VERSION ""

NS_ :

BS_:

BU_: mRFRM
VAL_TABLE_ VT_Fuse_status 3 "Not installed" 2 "Fault" 1 "Fuse powered" 0 "Fuse not powered" ;
VAL_TABLE_ VT_Relay_status 3 "Not installed" 2 "Reserved" 1 "Relay on" 0 "Relay off" ;
VAL_TABLE_ VT_Default_states 1 "Default state on" 0 "Default state off" ;
VAL_TABLE_ VT_Relay_state 3 "Do not change relay state" 2 "Reserved" 1 "Turn relay on" 0 "Turn relay off" ;

BO_ 2566698400 View_Fuse_Status: 8 mRFRM
 SG_ Fuse9_status : 22|2@1+ (1,0) [0|3] "" Vector__XXX
 SG_ Fuse8_status : 8|2@1+ (1,0) [0|3] "" Vector__XXX
 SG_ Fuse7_status : 10|2@1+ (1,0) [0|3] "" Vector__XXX
 SG_ Fuse6_status : 12|2@1+ (1,0) [0|3] "" Vector__XXX
 SG_ Fuse5_status : 14|2@1+ (1,0) [0|3] "" Vector__XXX
 SG_ Fuse4_status : 0|2@1+ (1,0) [0|3] "" Vector__XXX
 SG_ Fuse3_status : 2|2@1+ (1,0) [0|3] "" Vector__XXX
 SG_ Fuse2_status : 4|2@1+ (1,0) [0|3] "" Vector__XXX
 SG_ Fuse28_status : 48|2@1+ (1,0) [0|3] "" Vector__XXX
 SG_ Fuse27_status : 50|2@1+ (1,0) [0|3] "" Vector__XXX
 SG_ Fuse26_status : 52|2@1+ (1,0) [0|3] "" Vector__XXX
 SG_ Fuse25_status : 54|2@1+ (1,0) [0|3] "" Vector__XXX
 SG_ Fuse24_status : 40|2@1+ (1,0) [0|3] "" Vector__XXX
 SG_ Fuse23_status : 42|2@1+ (1,0) [0|3] "" Vector__XXX
 SG_ Fuse22_status : 44|2@1+ (1,0) [0|3] "" Vector__XXX
 SG_ Fuse21_status : 46|2@1+ (1,0) [0|3] "" Vector__XXX
 SG_ Fuse20_status : 32|2@1+ (1,0) [0|3] "" Vector__XXX
 SG_ Fuse1_status : 6|2@1+ (1,0) [0|3] "" Vector__XXX
 SG_ Fuse19_status : 34|2@1+ (1,0) [0|3] "" Vector__XXX
 SG_ Fuse18_status : 36|2@1+ (1,0) [0|3] "" Vector__XXX
 SG_ Fuse17_status : 38|2@1+ (1,0) [0|3] "" Vector__XXX
 SG_ Fuse16_status : 24|2@1+ (1,0) [0|3] "" Vector__XXX
 SG_ Fuse15_status : 26|2@1+ (1,0) [0|3] "" Vector__XXX
 SG_ Fuse14_status : 28|2@1+ (1,0) [0|3] "" Vector__XXX
 SG_ Fuse13_status : 30|2@1+ (1,0) [0|3] "" Vector__XXX
 SG_ Fuse12_status : 16|2@1+ (1,0) [0|3] "" Vector__XXX
 SG_ Fuse11_status : 18|2@1+ (1,0) [0|3] "" Vector__XXX
 SG_ Fuse10_status : 20|2@1+ (1,0) [0|3] "" Vector__XXX

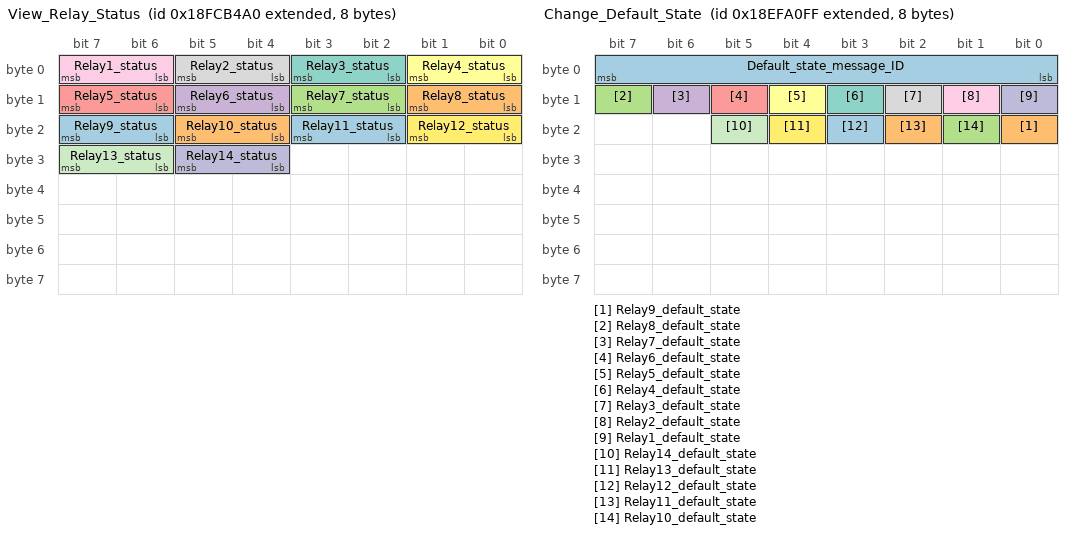
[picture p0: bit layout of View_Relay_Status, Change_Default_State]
BO_ 2566698144 View_Relay_Status: 8 mRFRM
 SG_ Relay9_status : 22|2@1+ (1,0) [0|3] "" Vector__XXX
 SG_ Relay8_status : 8|2@1+ (1,0) [0|3] "" Vector__XXX
 SG_ Relay7_status : 10|2@1+ (1,0) [0|3] "" Vector__XXX
 SG_ Relay6_status : 12|2@1+ (1,0) [0|3] "" Vector__XXX
 SG_ Relay5_status : 14|2@1+ (1,0) [0|3] "" Vector__XXX
 SG_ Relay4_status : 0|2@1+ (1,0) [0|3] "" Vector__XXX
 SG_ Relay3_status : 2|2@1+ (1,0) [0|3] "" Vector__XXX
 SG_ Relay2_status : 4|2@1+ (1,0) [0|3] "" Vector__XXX
 SG_ Relay1_status : 6|2@1+ (1,0) [0|3] "" Vector__XXX
 SG_ Relay14_status : 28|2@1+ (1,0) [0|3] "" Vector__XXX
 SG_ Relay13_status : 30|2@1+ (1,0) [0|3] "" Vector__XXX
 SG_ Relay12_status : 16|2@1+ (1,0) [0|3] "" Vector__XXX
 SG_ Relay11_status : 18|2@1+ (1,0) [0|3] "" Vector__XXX
 SG_ Relay10_status : 20|2@1+ (1,0) [0|3] "" Vector__XXX

BO_ 2565841151 Change_Default_State: 8 mRFRM
 SG_ Default_state_message_ID : 0|8@1+ (1,0) [0|255] "" Vector__XXX
 SG_ Relay9_default_state : 16|1@1+ (1,0) [0|1] "" Vector__XXX
 SG_ Relay8_default_state : 15|1@1+ (1,0) [0|1] "" Vector__XXX
 SG_ Relay7_default_state : 14|1@1+ (1,0) [0|1] "" Vector__XXX
 SG_ Relay6_default_state : 13|1@1+ (1,0) [0|1] "" Vector__XXX
 SG_ Relay5_default_state : 12|1@1+ (1,0) [0|1] "" Vector__XXX
 SG_ Relay4_default_state : 11|1@1+ (1,0) [0|1] "" Vector__XXX
 SG_ Relay3_default_state : 10|1@1+ (1,0) [0|1] "" Vector__XXX
 SG_ Relay2_default_state : 9|1@1+ (1,0) [0|1] "" Vector__XXX
 SG_ Relay1_default_state : 8|1@1+ (1,0) [0|1] "" Vector__XXX
 SG_ Relay14_default_state : 21|1@1+ (1,0) [0|1] "" Vector__XXX
 SG_ Relay13_default_state : 20|1@1+ (1,0) [0|1] "" Vector__XXX
 SG_ Relay12_default_state : 19|1@1+ (1,0) [0|1] "" Vector__XXX
 SG_ Relay11_default_state : 18|1@1+ (1,0) [0|1] "" Vector__XXX
 SG_ Relay10_default_state : 17|1@1+ (1,0) [0|1] "" Vector__XXX

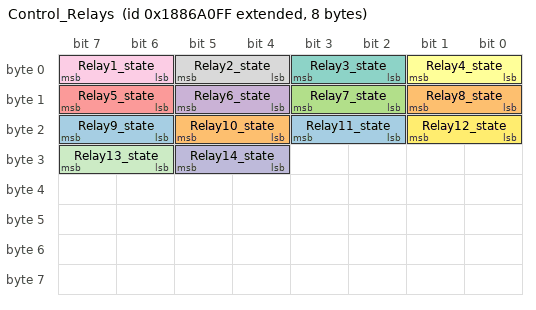
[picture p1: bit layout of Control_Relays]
BO_ 2558959871 Control_Relays: 8 mRFRM
 SG_ Relay9_state : 22|2@1+ (1,0) [0|3] "" Vector__XXX
 SG_ Relay8_state : 8|2@1+ (1,0) [0|3] "" Vector__XXX
 SG_ Relay7_state : 10|2@1+ (1,0) [0|3] "" Vector__XXX
 SG_ Relay6_state : 12|2@1+ (1,0) [0|3] "" Vector__XXX
 SG_ Relay5_state : 14|2@1+ (1,0) [0|3] "" Vector__XXX
 SG_ Relay4_state : 0|2@1+ (1,0) [0|3] "" Vector__XXX
 SG_ Relay3_state : 2|2@1+ (1,0) [0|3] "" Vector__XXX
 SG_ Relay2_state : 4|2@1+ (1,0) [0|3] "" Vector__XXX
 SG_ Relay1_state : 6|2@1+ (1,0) [0|3] "" Vector__XXX
 SG_ Relay14_state : 28|2@1+ (1,0) [0|3] "" Vector__XXX
 SG_ Relay13_state : 30|2@1+ (1,0) [0|3] "" Vector__XXX
 SG_ Relay12_state : 16|2@1+ (1,0) [0|3] "" Vector__XXX
 SG_ Relay11_state : 18|2@1+ (1,0) [0|3] "" Vector__XXX
 SG_ Relay10_state : 20|2@1+ (1,0) [0|3] "" Vector__XXX

CM_ BO_ 2565841151 "Set message ID to 0x79 to change default state";
BA_DEF_ SG_  "SigType" ENUM  "Default","Range","RangeSigned","ASCII","Discrete","Control","ReferencePGN","DTC","StringDelimiter","StringLength","StringLengthControl","MessageCounter","MessageChecksum";
BA_DEF_ SG_  "GenSigEVName" STRING ;
BA_DEF_ SG_  "GenSigILSupport" ENUM  "No","Yes";
BA_DEF_ SG_  "GenSigSendType" ENUM  "Cyclic","OnWrite","OnWriteWithRepetition","OnChange","OnChangeWithRepetition","IfActive","IfActiveWithRepetition","NoSigSendType";
BA_DEF_ BO_  "GenMsgCycleTimeFast" INT 0 3600000;
BA_DEF_ BO_  "GenMsgILSupport" ENUM  "No","Yes";
BA_DEF_ BO_  "GenMsgStartDelayTime" INT 0 100000;
BA_DEF_ BU_  "NmStationAddress" INT 0 255;
BA_DEF_ BO_  "GenMsgSendType" ENUM  "cyclic","NotUsed","IfActive","NotUsed","NotUsed","NotUsed","NotUsed","NotUsed","noMsgSendType";
BA_DEF_ BO_  "GenMsgRequestable" INT 0 1;
BA_DEF_ BO_  "GenMsgCycleTime" INT 0 3600000;
BA_DEF_  "DBName" STRING ;
BA_DEF_  "BusType" STRING ;
BA_DEF_DEF_  "SigType" "Default";
BA_DEF_DEF_  "GenSigEVName" "Env@Nodename_@Signame";
BA_DEF_DEF_  "GenSigILSupport" "Yes";
BA_DEF_DEF_  "GenSigSendType" "NoSigSendType";
BA_DEF_DEF_  "GenMsgCycleTimeFast" 0;
BA_DEF_DEF_  "GenMsgILSupport" "Yes";
BA_DEF_DEF_  "GenMsgStartDelayTime" 0;
BA_DEF_DEF_  "NmStationAddress" 254;
BA_DEF_DEF_  "GenMsgSendType" "noMsgSendType";
BA_DEF_DEF_  "GenMsgRequestable" 1;
BA_DEF_DEF_  "GenMsgCycleTime" 0;
BA_DEF_DEF_  "DBName" "";
BA_DEF_DEF_  "BusType" "CAN";
BA_ "DBName" "Node_mRFRM";
BA_ "GenMsgCycleTimeFast" BO_ 2558959871 100;
BA_ "GenMsgSendType" BO_ 2558959871 0;
BA_ "GenMsgCycleTime" BO_ 2558959871 100;
VAL_ 2566698400 Fuse9_status 3 "Not installed" 2 "Fault" 1 "Fuse powered" 0 "Fuse not powered" ;
VAL_ 2566698400 Fuse8_status 3 "Not installed" 2 "Fault" 1 "Fuse powered" 0 "Fuse not powered" ;
VAL_ 2566698400 Fuse7_status 3 "Not installed" 2 "Fault" 1 "Fuse powered" 0 "Fuse not powered" ;
VAL_ 2566698400 Fuse6_status 3 "Not installed" 2 "Fault" 1 "Fuse powered" 0 "Fuse not powered" ;
VAL_ 2566698400 Fuse5_status 3 "Not installed" 2 "Fault" 1 "Fuse powered" 0 "Fuse not powered" ;
VAL_ 2566698400 Fuse4_status 3 "Not installed" 2 "Fault" 1 "Fuse powered" 0 "Fuse not powered" ;
VAL_ 2566698400 Fuse3_status 3 "Not installed" 2 "Fault" 1 "Fuse powered" 0 "Fuse not powered" ;
VAL_ 2566698400 Fuse2_status 3 "Not installed" 2 "Fault" 1 "Fuse powered" 0 "Fuse not powered" ;
VAL_ 2566698400 Fuse28_status 3 "Not installed" 2 "Fault" 1 "Fuse powered" 0 "Fuse not powered" ;
VAL_ 2566698400 Fuse27_status 3 "Not installed" 2 "Fault" 1 "Fuse powered" 0 "Fuse not powered" ;
VAL_ 2566698400 Fuse26_status 3 "Not installed" 2 "Fault" 1 "Fuse powered" 0 "Fuse not powered" ;
VAL_ 2566698400 Fuse25_status 3 "Not installed" 2 "Fault" 1 "Fuse powered" 0 "Fuse not powered" ;
VAL_ 2566698400 Fuse24_status 3 "Not installed" 2 "Fault" 1 "Fuse powered" 0 "Fuse not powered" ;
VAL_ 2566698400 Fuse23_status 3 "Not installed" 2 "Fault" 1 "Fuse powered" 0 "Fuse not powered" ;
VAL_ 2566698400 Fuse22_status 3 "Not installed" 2 "Fault" 1 "Fuse powered" 0 "Fuse not powered" ;
VAL_ 2566698400 Fuse21_status 3 "Not installed" 2 "Fault" 1 "Fuse powered" 0 "Fuse not powered" ;
VAL_ 2566698400 Fuse20_status 3 "Not installed" 2 "Fault" 1 "Fuse powered" 0 "Fuse not powered" ;
VAL_ 2566698400 Fuse1_status 3 "Not installed" 2 "Fault" 1 "Fuse powered" 0 "Fuse not powered" ;
VAL_ 2566698400 Fuse19_status 3 "Not installed" 2 "Fault" 1 "Fuse powered" 0 "Fuse not powered" ;
VAL_ 2566698400 Fuse18_status 3 "Not installed" 2 "Fault" 1 "Fuse powered" 0 "Fuse not powered" ;
VAL_ 2566698400 Fuse17_status 3 "Not installed" 2 "Fault" 1 "Fuse powered" 0 "Fuse not powered" ;
VAL_ 2566698400 Fuse16_status 3 "Not installed" 2 "Fault" 1 "Fuse powered" 0 "Fuse not powered" ;
VAL_ 2566698400 Fuse15_status 3 "Not installed" 2 "Fault" 1 "Fuse powered" 0 "Fuse not powered" ;
VAL_ 2566698400 Fuse14_status 3 "Not installed" 2 "Fault" 1 "Fuse powered" 0 "Fuse not powered" ;
VAL_ 2566698400 Fuse13_status 3 "Not installed" 2 "Fault" 1 "Fuse powered" 0 "Fuse not powered" ;
VAL_ 2566698400 Fuse12_status 3 "Not installed" 2 "Fault" 1 "Fuse powered" 0 "Fuse not powered" ;
VAL_ 2566698400 Fuse11_status 3 "Not installed" 2 "Fault" 1 "Fuse powered" 0 "Fuse not powered" ;
VAL_ 2566698400 Fuse10_status 3 "Not installed" 2 "Fault" 1 "Fuse powered" 0 "Fuse not powered" ;
VAL_ 2566698144 Relay9_status 3 "Not installed" 2 "Reserved" 1 "Relay on" 0 "Relay off" ;
VAL_ 2566698144 Relay8_status 3 "Not installed" 2 "Reserved" 1 "Relay on" 0 "Relay off" ;
VAL_ 2566698144 Relay7_status 3 "Not installed" 2 "Reserved" 1 "Relay on" 0 "Relay off" ;
VAL_ 2566698144 Relay6_status 3 "Not installed" 2 "Reserved" 1 "Relay on" 0 "Relay off" ;
VAL_ 2566698144 Relay5_status 3 "Not installed" 2 "Reserved" 1 "Relay on" 0 "Relay off" ;
VAL_ 2566698144 Relay4_status 3 "Not installed" 2 "Reserved" 1 "Relay on" 0 "Relay off" ;
VAL_ 2566698144 Relay3_status 3 "Not installed" 2 "Reserved" 1 "Relay on" 0 "Relay off" ;
VAL_ 2566698144 Relay2_status 3 "Not installed" 2 "Reserved" 1 "Relay on" 0 "Relay off" ;
VAL_ 2566698144 Relay1_status 3 "Not installed" 2 "Reserved" 1 "Relay on" 0 "Relay off" ;
VAL_ 2566698144 Relay14_status 3 "Not installed" 2 "Reserved" 1 "Relay on" 0 "Relay off" ;
VAL_ 2566698144 Relay13_status 3 "Not installed" 2 "Reserved" 1 "Relay on" 0 "Relay off" ;
VAL_ 2566698144 Relay12_status 3 "Not installed" 2 "Reserved" 1 "Relay on" 0 "Relay off" ;
VAL_ 2566698144 Relay11_status 3 "Not installed" 2 "Reserved" 1 "Relay on" 0 "Relay off" ;
VAL_ 2566698144 Relay10_status 3 "Not installed" 2 "Reserved" 1 "Relay on" 0 "Relay off" ;
VAL_ 2565841151 Relay9_default_state 1 "Default state on" 0 "Default state off" ;
VAL_ 2565841151 Relay8_default_state 1 "Default state on" 0 "Default state off" ;
VAL_ 2565841151 Relay7_default_state 1 "Default state on" 0 "Default state off" ;
VAL_ 2565841151 Relay6_default_state 1 "Default state on" 0 "Default state off" ;
VAL_ 2565841151 Relay5_default_state 1 "Default state on" 0 "Default state off" ;
VAL_ 2565841151 Relay4_default_state 1 "Default state on" 0 "Default state off" ;
VAL_ 2565841151 Relay3_default_state 1 "Default state on" 0 "Default state off" ;
VAL_ 2565841151 Relay2_default_state 1 "Default state on" 0 "Default state off" ;
VAL_ 2565841151 Relay1_default_state 1 "Default state on" 0 "Default state off" ;
VAL_ 2565841151 Relay14_default_state 1 "Default state on" 0 "Default state off" ;
VAL_ 2565841151 Relay13_default_state 1 "Default state on" 0 "Default state off" ;
VAL_ 2565841151 Relay12_default_state 1 "Default state on" 0 "Default state off" ;
VAL_ 2565841151 Relay11_default_state 1 "Default state on" 0 "Default state off" ;
VAL_ 2565841151 Relay10_default_state 1 "Default state on" 0 "Default state off" ;
VAL_ 2558959871 Relay9_state 3 "Do not change relay state" 2 "Reserved" 1 "Turn relay on" 0 "Turn relay off" ;
VAL_ 2558959871 Relay8_state 3 "Do not change relay state" 2 "Reserved" 1 "Turn relay on" 0 "Turn relay off" ;
VAL_ 2558959871 Relay7_state 3 "Do not change relay state" 2 "Reserved" 1 "Turn relay on" 0 "Turn relay off" ;
VAL_ 2558959871 Relay6_state 3 "Do not change relay state" 2 "Reserved" 1 "Turn relay on" 0 "Turn relay off" ;
VAL_ 2558959871 Relay5_state 3 "Do not change relay state" 2 "Reserved" 1 "Turn relay on" 0 "Turn relay off" ;
VAL_ 2558959871 Relay4_state 3 "Do not change relay state" 2 "Reserved" 1 "Turn relay on" 0 "Turn relay off" ;
VAL_ 2558959871 Relay3_state 3 "Do not change relay state" 2 "Reserved" 1 "Turn relay on" 0 "Turn relay off" ;
VAL_ 2558959871 Relay2_state 3 "Do not change relay state" 2 "Reserved" 1 "Turn relay on" 0 "Turn relay off" ;
VAL_ 2558959871 Relay1_state 3 "Do not change relay state" 2 "Reserved" 1 "Turn relay on" 0 "Turn relay off" ;
VAL_ 2558959871 Relay14_state 3 "Do not change relay state" 2 "Reserved" 1 "Turn relay on" 0 "Turn relay off" ;
VAL_ 2558959871 Relay13_state 3 "Do not change relay state" 2 "Reserved" 1 "Turn relay on" 0 "Turn relay off" ;
VAL_ 2558959871 Relay12_state 3 "Do not change relay state" 2 "Reserved" 1 "Turn relay on" 0 "Turn relay off" ;
VAL_ 2558959871 Relay11_state 3 "Do not change relay state" 2 "Reserved" 1 "Turn relay on" 0 "Turn relay off" ;
VAL_ 2558959871 Relay10_state 3 "Do not change relay state" 2 "Reserved" 1 "Turn relay on" 0 "Turn relay off" ;
